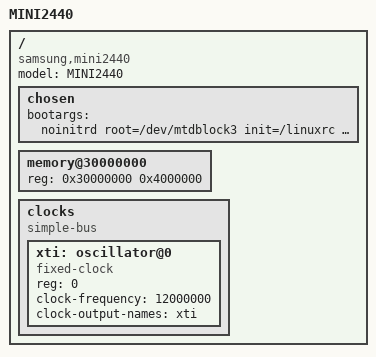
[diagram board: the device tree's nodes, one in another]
// SPDX-License-Identifier: GPL-2.0
/*
 * Samsung's S3C2416 SoC device tree source
 *
 * Copyright (c) 2013 Heiko Stuebner <heiko@sntech.de>
 */

/dts-v1/;
#include "s3c2440.dtsi"

/ {
	model = "MINI2440";
	compatible = "samsung,mini2440";

	chosen {
                bootargs = "noinitrd root=/dev/mtdblock3 init=/linuxrc console=ttySAC0,115200 rootfstype=yaffs2 rw";
        };

	memory@30000000 {
		device_type = "memory";
		reg =  <0x30000000 0x4000000>;
	};

        clocks {
         compatible = "simple-bus";
         #address-cells = <1>;
         #size-cells = <0>;
         xti: oscillator@0 {
             compatible = "fixed-clock";
             reg = <0>;
             clock-frequency = <12000000>;
             clock-output-names = "xti";
             #clock-cells = <0>;
         };
     };
};
